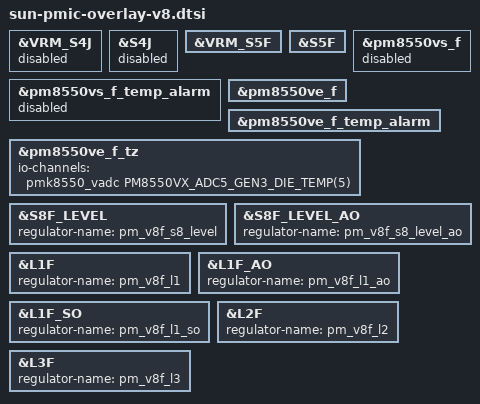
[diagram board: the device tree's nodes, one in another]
// SPDX-License-Identifier: BSD-3-Clause
/*
 * Copyright (c) 2023-2024 Qualcomm Innovation Center, Inc. All rights reserved.
 */

&VRM_S4J {
	status = "disabled";
};

&S4J {
	status = "disabled";
};

&VRM_S5F {
	status = "ok";
};

&S5F {
	status = "ok";
};

&pm8550vs_f {
	status = "disabled";
};

&pm8550vs_f_temp_alarm {
	status = "disabled";
};

&pm8550ve_f {
	status = "ok";
};

&pm8550ve_f_temp_alarm {
	status = "ok";
};

&pm8550ve_f_tz {
	io-channels = <&pmk8550_vadc PM8550VX_ADC5_GEN3_DIE_TEMP(5)>;
	io-channel-names = "thermal";
};

&S8F_LEVEL {
	regulator-name = "pm_v8f_s8_level";
};

&S8F_LEVEL_AO {
	regulator-name = "pm_v8f_s8_level_ao";
};

&L1F {
	regulator-name = "pm_v8f_l1";
};

&L1F_AO {
	regulator-name = "pm_v8f_l1_ao";
};

&L1F_SO {
	regulator-name = "pm_v8f_l1_so";
};

&L2F {
	regulator-name = "pm_v8f_l2";
};

&L3F {
	regulator-name = "pm_v8f_l3";
};
